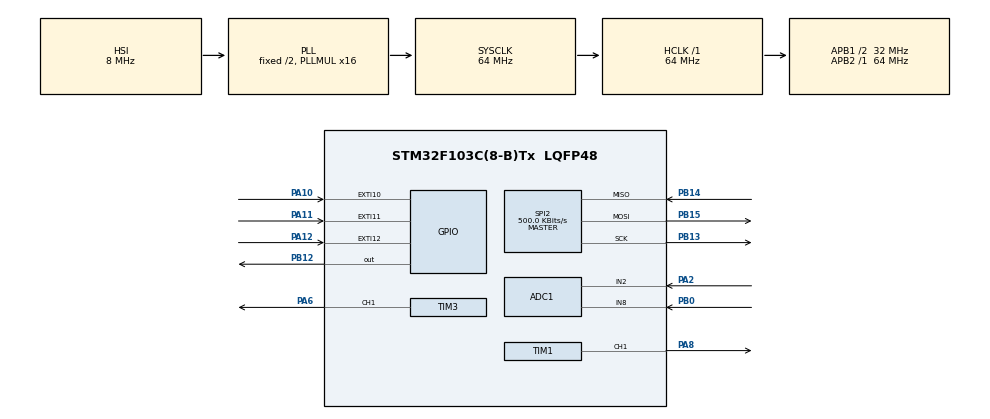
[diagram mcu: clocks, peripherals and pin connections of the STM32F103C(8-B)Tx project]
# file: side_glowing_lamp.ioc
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ADC1.Channel-4\#ChannelRegularConversion=ADC_CHANNEL_2
ADC1.Channel-5\#ChannelRegularConversion=ADC_CHANNEL_8
ADC1.Channel-6\#ChannelRegularConversion=ADC_CHANNEL_TEMPSENSOR
ADC1.Channel-7\#ChannelRegularConversion=ADC_CHANNEL_VREFINT
ADC1.ContinuousConvMode=ENABLE
ADC1.EnableRegularConversion=ENABLE
ADC1.NbrOfConversion=4
ADC1.NbrOfConversionFlag=1
ADC1.Rank-4\#ChannelRegularConversion=1
ADC1.Rank-5\#ChannelRegularConversion=2
ADC1.Rank-6\#ChannelRegularConversion=3
ADC1.Rank-7\#ChannelRegularConversion=4
ADC1.SamplingTime-4\#ChannelRegularConversion=ADC_SAMPLETIME_239CYCLES_5
ADC1.SamplingTime-5\#ChannelRegularConversion=ADC_SAMPLETIME_239CYCLES_5
ADC1.SamplingTime-6\#ChannelRegularConversion=ADC_SAMPLETIME_239CYCLES_5
ADC1.SamplingTime-7\#ChannelRegularConversion=ADC_SAMPLETIME_239CYCLES_5
ADC1.master=1
Dma.ADC1.1.Direction=DMA_PERIPH_TO_MEMORY
Dma.ADC1.1.Instance=DMA1_Channel1
Dma.ADC1.1.MemDataAlignment=DMA_MDATAALIGN_HALFWORD
Dma.ADC1.1.MemInc=DMA_MINC_ENABLE
Dma.ADC1.1.Mode=DMA_CIRCULAR
Dma.ADC1.1.PeriphDataAlignment=DMA_PDATAALIGN_HALFWORD
Dma.ADC1.1.PeriphInc=DMA_PINC_DISABLE
Dma.ADC1.1.Priority=DMA_PRIORITY_LOW
Dma.Request0=TIM3_CH1/TRIG
Dma.Request1=ADC1
Dma.TIM3_CH1/TRIG.0.Direction=DMA_MEMORY_TO_PERIPH
Dma.TIM3_CH1/TRIG.0.Instance=DMA1_Channel6
Dma.TIM3_CH1/TRIG.0.MemDataAlignment=DMA_MDATAALIGN_BYTE
Dma.TIM3_CH1/TRIG.0.MemInc=DMA_MINC_ENABLE
Dma.TIM3_CH1/TRIG.0.Mode=DMA_CIRCULAR
Dma.TIM3_CH1/TRIG.0.PeriphDataAlignment=DMA_PDATAALIGN_HALFWORD
Dma.TIM3_CH1/TRIG.0.PeriphInc=DMA_PINC_DISABLE
Dma.TIM3_CH1/TRIG.0.Priority=DMA_PRIORITY_MEDIUM
FREERTOS.Tasks01=monitorTask,24,64,MonitorTask,As weak,NULL,Dynamic,NULL,NULL;fadeOutLeds,8,128,FadeOutLedsTask,As weak,NULL,Dynamic,NULL,NULL
FREERTOS.configMINIMAL_STACK_SIZE=64
Mcu.Family=STM32F1
Mcu.Name=STM32F103C(8-B)Tx
Mcu.Package=LQFP48
NVIC.DMA1_Channel1_IRQn=true\:6\:0\:true\:false\:true\:true\:false\:true
NVIC.DMA1_Channel6_IRQn=true\:7\:0\:true\:false\:true\:true\:false\:true
NVIC.EXTI15_10_IRQn=true\:6\:0\:true\:false\:true\:true\:true\:true
NVIC.PriorityGroup=NVIC_PRIORITYGROUP_4
NVIC.TIM4_IRQn=true\:0\:0\:false\:false\:true\:false\:false\:true
NVIC.TimeBase=TIM4_IRQn
NVIC.TimeBaseIP=TIM4
PA10.GPIO_ModeDefaultEXTI=GPIO_MODE_IT_RISING_FALLING
PA10.GPIO_PuPd=GPIO_PULLUP
PA10.Signal=GPXTI10
PA11.GPIO_ModeDefaultEXTI=GPIO_MODE_IT_RISING_FALLING
PA11.GPIO_PuPd=GPIO_PULLUP
PA11.Signal=GPXTI11
PA12.GPIO_ModeDefaultEXTI=GPIO_MODE_IT_RISING_FALLING
PA12.GPIO_PuPd=GPIO_PULLUP
PA12.Signal=GPXTI12
PA13.Mode=Serial_Wire
PA13.Signal=SYS_JTMS-SWDIO
PA14.Mode=Serial_Wire
PA14.Signal=SYS_JTCK-SWCLK
PA2.Signal=ADCx_IN2
PA6.Signal=S_TIM3_CH1
PA8.Signal=S_TIM1_CH1
PB0.Signal=ADCx_IN8
PB12.Signal=GPIO_Output
PB13.Mode=Full_Duplex_Master
PB13.Signal=SPI2_SCK
PB14.Mode=Full_Duplex_Master
PB14.Signal=SPI2_MISO
PB15.Mode=Full_Duplex_Master
PB15.Signal=SPI2_MOSI
ProjectManager.HeapSize=0x200
ProjectManager.StackSize=0x400
ProjectManager.TargetToolchain=STM32CubeIDE
RCC.ADCPresc=RCC_ADCPCLK2_DIV8
RCC.AHBFreq_Value=64000000
RCC.APB1CLKDivider=RCC_HCLK_DIV2
RCC.APB1Freq_Value=32000000
RCC.APB1TimFreq_Value=64000000
RCC.APB2Freq_Value=64000000
RCC.APB2TimFreq_Value=64000000
RCC.HCLKFreq_Value=64000000
RCC.PLLMUL=RCC_PLL_MUL16
RCC.SYSCLKFreq_VALUE=64000000
RCC.SYSCLKSource=RCC_SYSCLKSOURCE_PLLCLK
RCC.USBFreq_Value=64000000
SH.ADCx_IN2.0=ADC1_IN2,IN2
SH.ADCx_IN8.0=ADC1_IN8,IN8
SH.S_TIM1_CH1.0=TIM1_CH1,PWM Generation1 CH1
SH.S_TIM3_CH1.0=TIM3_CH1,PWM Generation1 CH1
SPI2.BaudRatePrescaler=SPI_BAUDRATEPRESCALER_64
SPI2.CalculateBaudRate=500.0 KBits/s
SPI2.Direction=SPI_DIRECTION_2LINES
SPI2.Mode=SPI_MODE_MASTER
SPI2.VirtualType=VM_MASTER
TIM1.Channel-PWM\ Generation1\ CH1=TIM_CHANNEL_1
TIM1.Period=100
TIM1.Prescaler=480
TIM3.AutoReloadPreload=TIM_AUTORELOAD_PRELOAD_ENABLE
TIM3.Channel-PWM\ Generation1\ CH1=TIM_CHANNEL_1
TIM3.Period=80
VP_ADC1_TempSens_Input.Mode=IN-TempSens
VP_ADC1_Vref_Input.Mode=IN-Vrefint
VP_FREERTOS_VS_CMSIS_V2.Mode=CMSIS_V2
VP_SYS_VS_tim4.Mode=TIM4
VP_TIM1_VS_ClockSourceINT.Mode=Internal
VP_TIM3_VS_ClockSourceINT.Mode=Internal
board=custom

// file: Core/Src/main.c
/* USER CODE BEGIN Header */
/**
 ******************************************************************************
 * @file           : main.c
 * @brief          : Main program body
 ******************************************************************************
 * @attention
 *
 * <h2><center>&copy; Copyright (c) 2020 STMicroelectronics.
 * All rights reserved.</center></h2>
 *
 * This software component is licensed by ST under Ultimate Liberty license
 * SLA0044, the "License"; You may not use this file except in compliance with
 * the License. You may obtain a copy of the License at:
 *                             www.st.com/SLA0044
 *
 ******************************************************************************
 */
/* USER CODE END Header */
#include "main.h"
#include "cmsis_os.h"

/* USER CODE BEGIN Includes */
#include "init.h"
#include "leds.h"
/* USER CODE END Includes */

ADC_HandleTypeDef hadc1;
DMA_HandleTypeDef hdma_adc1;

SPI_HandleTypeDef hspi2;

TIM_HandleTypeDef htim1;
TIM_HandleTypeDef htim3;
DMA_HandleTypeDef hdma_tim3_ch1_trig;

/* Definitions for monitorTask */
osThreadId_t monitorTaskHandle;
const osThreadAttr_t monitorTask_attributes = {
  .name = "monitorTask",
  .priority = (osPriority_t) osPriorityNormal,
  .stack_size = 64 * 4
};
/* Definitions for fadeOutLeds */
osThreadId_t fadeOutLedsHandle;
const osThreadAttr_t fadeOutLeds_attributes = {
  .name = "fadeOutLeds",
  .priority = (osPriority_t) osPriorityLow,
  .stack_size = 128 * 4
};

void SystemClock_Config(void);
static void MX_GPIO_Init(void);
static void MX_DMA_Init(void);
static void MX_TIM1_Init(void);
static void MX_ADC1_Init(void);
static void MX_SPI2_Init(void);
static void MX_TIM3_Init(void);
void MonitorTask(void *argument);
void FadeOutLedsTask(void *argument);

int main(void)
{

  /* MCU Configuration--------------------------------------------------------*/

  /* Reset of all peripherals, Initializes the Flash interface and the Systick. */
  HAL_Init();

  /* Configure the system clock */
  SystemClock_Config();

  /* Initialize all configured peripherals */
  MX_GPIO_Init();
  MX_DMA_Init();
  MX_TIM1_Init();
  MX_ADC1_Init();
  MX_SPI2_Init();
  MX_TIM3_Init();
  /* USER CODE BEGIN 2 */
	initDevice();
  /* USER CODE END 2 */

  /* Init scheduler */
  osKernelInitialize();

  /* Create the thread(s) */
  /* creation of monitorTask */
  monitorTaskHandle = osThreadNew(MonitorTask, NULL, &monitorTask_attributes);

  /* creation of fadeOutLeds */
  fadeOutLedsHandle = osThreadNew(FadeOutLedsTask, NULL, &fadeOutLeds_attributes);

  /* Start scheduler */
  osKernelStart();

  /* We should never get here as control is now taken by the scheduler */
  /* Infinite loop */
	while (1)
	{

	}
}

void SystemClock_Config(void)
{
  RCC_OscInitTypeDef RCC_OscInitStruct = {0};
  RCC_ClkInitTypeDef RCC_ClkInitStruct = {0};
  RCC_PeriphCLKInitTypeDef PeriphClkInit = {0};

  /** Initializes the RCC Oscillators according to the specified parameters
  * in the RCC_OscInitTypeDef structure.
  */
  RCC_OscInitStruct.OscillatorType = RCC_OSCILLATORTYPE_HSI;
  RCC_OscInitStruct.HSIState = RCC_HSI_ON;
  RCC_OscInitStruct.HSICalibrationValue = RCC_HSICALIBRATION_DEFAULT;
  RCC_OscInitStruct.PLL.PLLState = RCC_PLL_ON;
  RCC_OscInitStruct.PLL.PLLSource = RCC_PLLSOURCE_HSI_DIV2;
  RCC_OscInitStruct.PLL.PLLMUL = RCC_PLL_MUL16;
  if (HAL_RCC_OscConfig(&RCC_OscInitStruct) != HAL_OK)
  {
    Error_Handler();
  }
  /** Initializes the CPU, AHB and APB buses clocks
  */
  RCC_ClkInitStruct.ClockType = RCC_CLOCKTYPE_HCLK|RCC_CLOCKTYPE_SYSCLK
                              |RCC_CLOCKTYPE_PCLK1|RCC_CLOCKTYPE_PCLK2;
  RCC_ClkInitStruct.SYSCLKSource = RCC_SYSCLKSOURCE_PLLCLK;
  RCC_ClkInitStruct.AHBCLKDivider = RCC_SYSCLK_DIV1;
  RCC_ClkInitStruct.APB1CLKDivider = RCC_HCLK_DIV2;
  RCC_ClkInitStruct.APB2CLKDivider = RCC_HCLK_DIV1;

  if (HAL_RCC_ClockConfig(&RCC_ClkInitStruct, FLASH_LATENCY_2) != HAL_OK)
  {
    Error_Handler();
  }
  PeriphClkInit.PeriphClockSelection = RCC_PERIPHCLK_ADC;
  PeriphClkInit.AdcClockSelection = RCC_ADCPCLK2_DIV8;
  if (HAL_RCCEx_PeriphCLKConfig(&PeriphClkInit) != HAL_OK)
  {
    Error_Handler();
  }
}

static void MX_ADC1_Init(void)
{

  ADC_ChannelConfTypeDef sConfig = {0};

  /** Common config
  */
  hadc1.Instance = ADC1;
  hadc1.Init.ScanConvMode = ADC_SCAN_ENABLE;
  hadc1.Init.ContinuousConvMode = ENABLE;
  hadc1.Init.DiscontinuousConvMode = DISABLE;
  hadc1.Init.ExternalTrigConv = ADC_SOFTWARE_START;
  hadc1.Init.DataAlign = ADC_DATAALIGN_RIGHT;
  hadc1.Init.NbrOfConversion = 4;
  if (HAL_ADC_Init(&hadc1) != HAL_OK)
  {
    Error_Handler();
  }
  /** Configure Regular Channel
  */
  sConfig.Channel = ADC_CHANNEL_2;
  sConfig.Rank = ADC_REGULAR_RANK_1;
  sConfig.SamplingTime = ADC_SAMPLETIME_239CYCLES_5;
  if (HAL_ADC_ConfigChannel(&hadc1, &sConfig) != HAL_OK)
  {
    Error_Handler();
  }
  /** Configure Regular Channel
  */
  sConfig.Channel = ADC_CHANNEL_8;
  sConfig.Rank = ADC_REGULAR_RANK_2;
  if (HAL_ADC_ConfigChannel(&hadc1, &sConfig) != HAL_OK)
  {
    Error_Handler();
  }
  /** Configure Regular Channel
  */
  sConfig.Channel = ADC_CHANNEL_TEMPSENSOR;
  sConfig.Rank = ADC_REGULAR_RANK_3;
  if (HAL_ADC_ConfigChannel(&hadc1, &sConfig) != HAL_OK)
  {
    Error_Handler();
  }
  /** Configure Regular Channel
  */
  sConfig.Channel = ADC_CHANNEL_VREFINT;
  sConfig.Rank = ADC_REGULAR_RANK_4;
  if (HAL_ADC_ConfigChannel(&hadc1, &sConfig) != HAL_OK)
  {
    Error_Handler();
  }

}

static void MX_SPI2_Init(void)
{

  /* SPI2 parameter configuration*/
  hspi2.Instance = SPI2;
  hspi2.Init.Mode = SPI_MODE_MASTER;
  hspi2.Init.Direction = SPI_DIRECTION_2LINES;
  hspi2.Init.DataSize = SPI_DATASIZE_8BIT;
  hspi2.Init.CLKPolarity = SPI_POLARITY_LOW;
  hspi2.Init.CLKPhase = SPI_PHASE_1EDGE;
  hspi2.Init.NSS = SPI_NSS_SOFT;
  hspi2.Init.BaudRatePrescaler = SPI_BAUDRATEPRESCALER_64;
  hspi2.Init.FirstBit = SPI_FIRSTBIT_MSB;
  hspi2.Init.TIMode = SPI_TIMODE_DISABLE;
  hspi2.Init.CRCCalculation = SPI_CRCCALCULATION_DISABLE;
  hspi2.Init.CRCPolynomial = 10;
  if (HAL_SPI_Init(&hspi2) != HAL_OK)
  {
    Error_Handler();
  }

}

static void MX_TIM1_Init(void)
{

  TIM_ClockConfigTypeDef sClockSourceConfig = {0};
  TIM_MasterConfigTypeDef sMasterConfig = {0};
  TIM_OC_InitTypeDef sConfigOC = {0};
  TIM_BreakDeadTimeConfigTypeDef sBreakDeadTimeConfig = {0};

  htim1.Instance = TIM1;
  htim1.Init.Prescaler = 480;
  htim1.Init.CounterMode = TIM_COUNTERMODE_UP;
  htim1.Init.Period = 100;
  htim1.Init.ClockDivision = TIM_CLOCKDIVISION_DIV1;
  htim1.Init.RepetitionCounter = 0;
  htim1.Init.AutoReloadPreload = TIM_AUTORELOAD_PRELOAD_DISABLE;
  if (HAL_TIM_Base_Init(&htim1) != HAL_OK)
  {
    Error_Handler();
  }
  sClockSourceConfig.ClockSource = TIM_CLOCKSOURCE_INTERNAL;
  if (HAL_TIM_ConfigClockSource(&htim1, &sClockSourceConfig) != HAL_OK)
  {
    Error_Handler();
  }
  if (HAL_TIM_PWM_Init(&htim1) != HAL_OK)
  {
    Error_Handler();
  }
  sMasterConfig.MasterOutputTrigger = TIM_TRGO_RESET;
  sMasterConfig.MasterSlaveMode = TIM_MASTERSLAVEMODE_DISABLE;
  if (HAL_TIMEx_MasterConfigSynchronization(&htim1, &sMasterConfig) != HAL_OK)
  {
    Error_Handler();
  }
  sConfigOC.OCMode = TIM_OCMODE_PWM1;
  sConfigOC.Pulse = 0;
  sConfigOC.OCPolarity = TIM_OCPOLARITY_HIGH;
  sConfigOC.OCNPolarity = TIM_OCNPOLARITY_HIGH;
  sConfigOC.OCFastMode = TIM_OCFAST_DISABLE;
  sConfigOC.OCIdleState = TIM_OCIDLESTATE_RESET;
  sConfigOC.OCNIdleState = TIM_OCNIDLESTATE_RESET;
  if (HAL_TIM_PWM_ConfigChannel(&htim1, &sConfigOC, TIM_CHANNEL_1) != HAL_OK)
  {
    Error_Handler();
  }
  sBreakDeadTimeConfig.OffStateRunMode = TIM_OSSR_DISABLE;
  sBreakDeadTimeConfig.OffStateIDLEMode = TIM_OSSI_DISABLE;
  sBreakDeadTimeConfig.LockLevel = TIM_LOCKLEVEL_OFF;
  sBreakDeadTimeConfig.DeadTime = 0;
  sBreakDeadTimeConfig.BreakState = TIM_BREAK_DISABLE;
  sBreakDeadTimeConfig.BreakPolarity = TIM_BREAKPOLARITY_HIGH;
  sBreakDeadTimeConfig.AutomaticOutput = TIM_AUTOMATICOUTPUT_DISABLE;
  if (HAL_TIMEx_ConfigBreakDeadTime(&htim1, &sBreakDeadTimeConfig) != HAL_OK)
  {
    Error_Handler();
  }
  HAL_TIM_MspPostInit(&htim1);

}

static void MX_TIM3_Init(void)
{

  TIM_ClockConfigTypeDef sClockSourceConfig = {0};
  TIM_MasterConfigTypeDef sMasterConfig = {0};
  TIM_OC_InitTypeDef sConfigOC = {0};

  htim3.Instance = TIM3;
  htim3.Init.Prescaler = 0;
  htim3.Init.CounterMode = TIM_COUNTERMODE_UP;
  htim3.Init.Period = 80;
  htim3.Init.ClockDivision = TIM_CLOCKDIVISION_DIV1;
  htim3.Init.AutoReloadPreload = TIM_AUTORELOAD_PRELOAD_ENABLE;
  if (HAL_TIM_Base_Init(&htim3) != HAL_OK)
  {
    Error_Handler();
  }
  sClockSourceConfig.ClockSource = TIM_CLOCKSOURCE_INTERNAL;
  if (HAL_TIM_ConfigClockSource(&htim3, &sClockSourceConfig) != HAL_OK)
  {
    Error_Handler();
  }
  if (HAL_TIM_PWM_Init(&htim3) != HAL_OK)
  {
    Error_Handler();
  }
  sMasterConfig.MasterOutputTrigger = TIM_TRGO_RESET;
  sMasterConfig.MasterSlaveMode = TIM_MASTERSLAVEMODE_DISABLE;
  if (HAL_TIMEx_MasterConfigSynchronization(&htim3, &sMasterConfig) != HAL_OK)
  {
    Error_Handler();
  }
  sConfigOC.OCMode = TIM_OCMODE_PWM1;
  sConfigOC.Pulse = 0;
  sConfigOC.OCPolarity = TIM_OCPOLARITY_HIGH;
  sConfigOC.OCFastMode = TIM_OCFAST_DISABLE;
  if (HAL_TIM_PWM_ConfigChannel(&htim3, &sConfigOC, TIM_CHANNEL_1) != HAL_OK)
  {
    Error_Handler();
  }
  HAL_TIM_MspPostInit(&htim3);

}

static void MX_DMA_Init(void)
{

  /* DMA controller clock enable */
  __HAL_RCC_DMA1_CLK_ENABLE();

  /* DMA interrupt init */
  /* DMA1_Channel1_IRQn interrupt configuration */
  HAL_NVIC_SetPriority(DMA1_Channel1_IRQn, 6, 0);
  HAL_NVIC_EnableIRQ(DMA1_Channel1_IRQn);
  /* DMA1_Channel6_IRQn interrupt configuration */
  HAL_NVIC_SetPriority(DMA1_Channel6_IRQn, 7, 0);
  HAL_NVIC_EnableIRQ(DMA1_Channel6_IRQn);

}

static void MX_GPIO_Init(void)
{
  GPIO_InitTypeDef GPIO_InitStruct = {0};

  /* GPIO Ports Clock Enable */
  __HAL_RCC_GPIOA_CLK_ENABLE();
  __HAL_RCC_GPIOB_CLK_ENABLE();

  /*Configure GPIO pin Output Level */
  HAL_GPIO_WritePin(GPIOB, GPIO_PIN_12, GPIO_PIN_RESET);

  /*Configure GPIO pin : PB12 */
  GPIO_InitStruct.Pin = GPIO_PIN_12;
  GPIO_InitStruct.Mode = GPIO_MODE_OUTPUT_PP;
  GPIO_InitStruct.Pull = GPIO_NOPULL;
  GPIO_InitStruct.Speed = GPIO_SPEED_FREQ_LOW;
  HAL_GPIO_Init(GPIOB, &GPIO_InitStruct);

  /*Configure GPIO pins : PA10 PA11 PA12 */
  GPIO_InitStruct.Pin = GPIO_PIN_10|GPIO_PIN_11|GPIO_PIN_12;
  GPIO_InitStruct.Mode = GPIO_MODE_IT_RISING_FALLING;
  GPIO_InitStruct.Pull = GPIO_PULLUP;
  HAL_GPIO_Init(GPIOA, &GPIO_InitStruct);

  /* EXTI interrupt init*/
  HAL_NVIC_SetPriority(EXTI15_10_IRQn, 6, 0);
  HAL_NVIC_EnableIRQ(EXTI15_10_IRQn);

}

__weak void MonitorTask(void *argument)
{
  /* USER CODE BEGIN 5 */
	/* Infinite loop */
	for(;;)
	{
		osDelay(2000);
	}
  /* USER CODE END 5 */
}

__weak void FadeOutLedsTask(void *argument)
{
  for(;;)
  {
    osDelay(1);
  }
}

 /**
  * @brief  Period elapsed callback in non blocking mode
  * @note   This function is called  when TIM4 interrupt took place, inside
  * HAL_TIM_IRQHandler(). It makes a direct call to HAL_IncTick() to increment
  * a global variable "uwTick" used as application time base.
  * @param  htim : TIM handle
  * @retval None
  */
void HAL_TIM_PeriodElapsedCallback(TIM_HandleTypeDef *htim)
{
  if (htim->Instance == TIM4) {
    HAL_IncTick();
  }
}

void Error_Handler(void)
{
}

/************************ (C) COPYRIGHT STMicroelectronics *****END OF FILE****/
